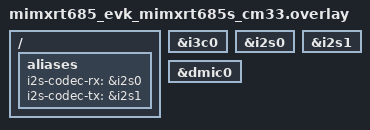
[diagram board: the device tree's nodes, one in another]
/ {
	aliases {
		i2s-codec-rx = &i2s0;
		i2s-codec-tx = &i2s1;
	};
};

&i3c0 {
	status = "okay";
};

&i2s0 {
	status = "okay";
};

&i2s1 {
	status = "okay";
};

dmic_dev: &dmic0 {
	status = "okay";
};
